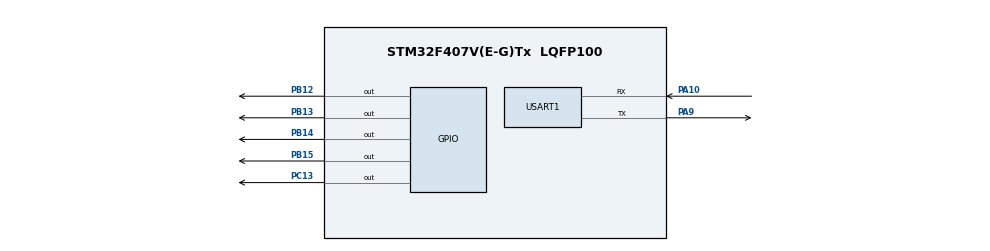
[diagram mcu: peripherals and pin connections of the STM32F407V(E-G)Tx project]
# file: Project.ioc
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Mcu.Family=STM32F4
Mcu.Name=STM32F407V(E-G)Tx
Mcu.Package=LQFP100
NVIC.PriorityGroup=NVIC_PRIORITYGROUP_4
NVIC.USART1_IRQn=true\:0\:0\:false\:false\:true\:true\:true\:true
PA10.Mode=Asynchronous
PA10.Signal=USART1_RX
PA13.Mode=Serial_Wire
PA13.Signal=SYS_JTMS-SWDIO
PA14.Mode=Serial_Wire
PA14.Signal=SYS_JTCK-SWCLK
PA9.Mode=Asynchronous
PA9.Signal=USART1_TX
PB12.GPIO_Speed=GPIO_SPEED_FREQ_VERY_HIGH
PB12.Signal=GPIO_Output
PB13.GPIO_Speed=GPIO_SPEED_FREQ_VERY_HIGH
PB13.Signal=GPIO_Output
PB14.GPIO_Speed=GPIO_SPEED_FREQ_VERY_HIGH
PB14.Signal=GPIO_Output
PB15.GPIO_Speed=GPIO_SPEED_FREQ_VERY_HIGH
PB15.Signal=GPIO_Output
PC13-ANTI_TAMP.GPIO_PuPd=GPIO_PULLUP
PC13-ANTI_TAMP.Signal=GPIO_Output
PC14-OSC32_IN.Mode=LSE-External-Oscillator
PC14-OSC32_IN.Signal=RCC_OSC32_IN
PC15-OSC32_OUT.Mode=LSE-External-Oscillator
PC15-OSC32_OUT.Signal=RCC_OSC32_OUT
PH0-OSC_IN.Mode=HSE-External-Oscillator
PH0-OSC_IN.Signal=RCC_OSC_IN
PH1-OSC_OUT.Mode=HSE-External-Oscillator
PH1-OSC_OUT.Signal=RCC_OSC_OUT
ProjectManager.HeapSize=0x200
ProjectManager.StackSize=0x400
ProjectManager.TargetToolchain=MDK-ARM V5
RCC.48MHZClocksFreq_Value=84000000
RCC.AHBFreq_Value=168000000
RCC.APB1CLKDivider=RCC_HCLK_DIV4
RCC.APB1Freq_Value=42000000
RCC.APB1TimFreq_Value=84000000
RCC.APB2CLKDivider=RCC_HCLK_DIV2
RCC.APB2Freq_Value=84000000
RCC.APB2TimFreq_Value=168000000
RCC.CortexFreq_Value=168000000
RCC.HCLKFreq_Value=168000000
RCC.HSE_VALUE=25000000
RCC.HSI_VALUE=16000000
RCC.PLLM=25
RCC.PLLN=336
RCC.PLLSourceVirtual=RCC_PLLSOURCE_HSE
RCC.SYSCLKFreq_VALUE=168000000
RCC.SYSCLKSource=RCC_SYSCLKSOURCE_PLLCLK
RCC.VCOOutputFreq_Value=336000000
USART1.VirtualMode=VM_ASYNC
board=custom

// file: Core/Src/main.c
/* USER CODE BEGIN Header */
/**
 ******************************************************************************
 * @file           : main.c
 * @brief          : Main program body
 ******************************************************************************
 * @attention
 *
 * Copyright (c) 2024 STMicroelectronics.
 * All rights reserved.
 *
 * This software is licensed under terms that can be found in the LICENSE file
 * in the root directory of this software component.
 * If no LICENSE file comes with this software, it is provided AS-IS.
 *
 ******************************************************************************
 */
/* USER CODE END Header */
#include "main.h"
#include "usart.h"
#include "gpio.h"

/* USER CODE BEGIN Includes */
#include <stdio.h>
#include "Delay.h"
#include "AD9833.h"
#include "Serial.h"

/* USER CODE END Includes */

void SystemClock_Config(void);

int main(void)
{

  /* MCU Configuration--------------------------------------------------------*/

  /* Reset of all peripherals, Initializes the Flash interface and the Systick. */
  LL_APB2_GRP1_EnableClock(LL_APB2_GRP1_PERIPH_SYSCFG);
  LL_APB1_GRP1_EnableClock(LL_APB1_GRP1_PERIPH_PWR);

  /* System interrupt init*/
  NVIC_SetPriorityGrouping(NVIC_PRIORITYGROUP_4);

  /* SysTick_IRQn interrupt configuration */
  NVIC_SetPriority(SysTick_IRQn, NVIC_EncodePriority(NVIC_GetPriorityGrouping(), 15, 0));

  /* Configure the system clock */
  SystemClock_Config();

  /* Initialize all configured peripherals */
  // MX_GPIO_Init();
  MX_USART1_UART_Init();
  /* USER CODE BEGIN 2 */
  // AD9833_Init();
  // Delay_ms(1);
  // Ad9833_SetFrequency(500, 25000000);
  // Delay_ms(1);
  // AD9833_WaveMode(1);
  // Delay_ms(2);
  // Ad9833_single(1,500,2048);

  AD9833 *ad9833 = AD9833_Create(25000000, &AD9833_dev1);
  if (ad9833 != NULL)
  {
    AD9833_Init(ad9833);
  }
  ad9833->SetWave(ad9833, WAVE_SINE, WAVE_TRIANGLE, 10000, 10000, 2048, 0);
  // ad9833->WaveMode(ad9833, FSYNC_1, WAVE_TRIANGLE); // 设置波形模式为正弦波

  // AD9833_WaveMode(ad9833, FSYNC_BOTH, WAVE_SINE);
  // Delay_ms(1);
  // AD9833_SetFrequency(ad9833, FSYNC_BOTH, 1000);
  // Delay_ms(1);
  // AD9833_SetPhase(ad9833, FSYNC_BOTH, 2048);
  // Delay_ms(1);
  // AD9833_SetFrequency(ad9833, FSYNC_1, 3000);

  /* USER CODE END 2 */

  /* Infinite loop */
  while (1)
  {

    /* USER CODE BEGIN 3 */
    // LL_GPIO_SetOutputPin(GPIOC, LL_GPIO_PIN_13);
    // AD9833_WaveMode(3);
    // Delay_ms(2);
    // Ad9833_SetFrequency(1000, 25000000);
    // LL_GPIO_TogglePin(GPIOC, LL_GPIO_PIN_13);

    // if (Serial_GetRxFlag() == 1)
    // {
    //   USART_ComandTask(Serial_RxPacket[0]);
    // }

    // AD9833_WaveMode(3);
    // Delay_ms(2);
    // Ad9833_SetFrequency(10, 25000000);
    // Ad9833_SetFrequency(50, 25000000);
    // Delay_ms(500);
    // LL_GPIO_ResetOutputPin(GPIOC,LL_GPIO_PIN_13);
  }
  /* USER CODE END 3 */
}

void SystemClock_Config(void)
{
  LL_FLASH_SetLatency(LL_FLASH_LATENCY_5);
  while (LL_FLASH_GetLatency() != LL_FLASH_LATENCY_5)
  {
  }
  LL_PWR_SetRegulVoltageScaling(LL_PWR_REGU_VOLTAGE_SCALE1);
  LL_RCC_HSE_Enable();

  /* Wait till HSE is ready */
  while (LL_RCC_HSE_IsReady() != 1)
  {
  }
  LL_RCC_PLL_ConfigDomain_SYS(LL_RCC_PLLSOURCE_HSE, LL_RCC_PLLM_DIV_25, 336, LL_RCC_PLLP_DIV_2);
  LL_RCC_PLL_Enable();

  /* Wait till PLL is ready */
  while (LL_RCC_PLL_IsReady() != 1)
  {
  }
  while (LL_PWR_IsActiveFlag_VOS() == 0)
  {
  }
  LL_RCC_SetAHBPrescaler(LL_RCC_SYSCLK_DIV_1);
  LL_RCC_SetAPB1Prescaler(LL_RCC_APB1_DIV_4);
  LL_RCC_SetAPB2Prescaler(LL_RCC_APB2_DIV_2);
  LL_RCC_SetSysClkSource(LL_RCC_SYS_CLKSOURCE_PLL);

  /* Wait till System clock is ready */
  while (LL_RCC_GetSysClkSource() != LL_RCC_SYS_CLKSOURCE_STATUS_PLL)
  {
  }
  LL_Init1msTick(168000000);
  LL_SetSystemCoreClock(168000000);
}

void Error_Handler(void)
{
  __disable_irq();
  while (1)
  {
  }
}
